# STM32L4S5 register map
File version: 2.2
CPU: CM4 r0p1, little endian, MPU, FPU, 4 interrupt priority bits
Registers are 32-bit, read-write, reset 0x0 unless marked. A register's access mark holds for its fields unless they carry their own. Offsets are from the block's base; [hi:lo] are bit positions.

## OCTOSPI1 — OctoSPI
Base 0xA0001000
Same registers: OCTOSPI2 0xA0001400
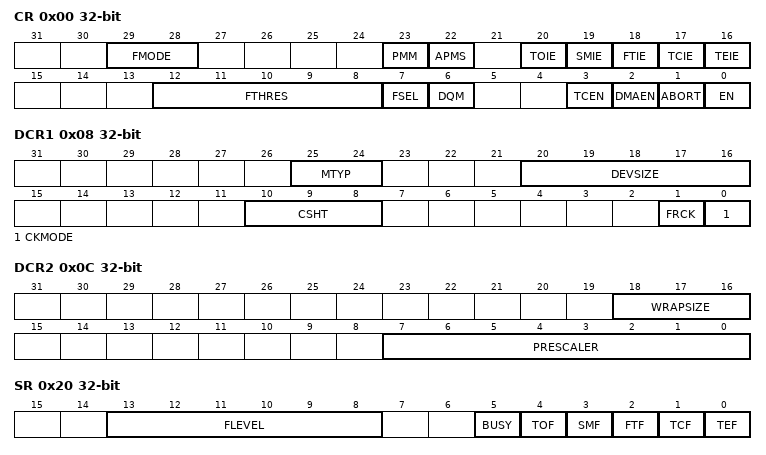
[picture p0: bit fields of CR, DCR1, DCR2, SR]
0x00 CR — control register
  [29:28] FMODE — Functional mode
  [23] PMM — Polling match mode
  [22] APMS — Automatic poll mode stop
  [20] TOIE — TimeOut interrupt enable
  [19] SMIE — Status match interrupt enable
  [18] FTIE — FIFO threshold interrupt enable
  [17] TCIE — Transfer complete interrupt enable
  [16] TEIE — Transfer error interrupt enable
  [12:8] FTHRES — IFO threshold level
  [7] FSEL — FLASH memory selection
  [6] DQM — Dual-quad mode
  [3] TCEN — Timeout counter enable
  [2] DMAEN — DMA enable
  [1] ABORT — Abort request
  [0] EN — Enable
0x08 DCR1 — device configuration register
  [25:24] MTYP — Memory type
  [20:16] DEVSIZE — Device size
  [10:8] CSHT — Chip-select high time
  [1] FRCK — Free running clock
  [0] CKMODE — Mode 0 / mode 3
0x0C DCR2 — device configuration register 2
  [18:16] WRAPSIZE
  [7:0] PRESCALER — Clock prescaler
0x10 DCR3 — device configuration register 3
  [20:16] CSBOUND — CS boundary
0x20 SR — status register
  [13:8] FLEVEL — FIFO level
  [5] BUSY
  [4] TOF — Timeout flag
  [3] SMF — Status match flag
  [2] FTF — FIFO threshold flag
  [1] TCF — Transfer complete flag
  [0] TEF — Transfer error flag
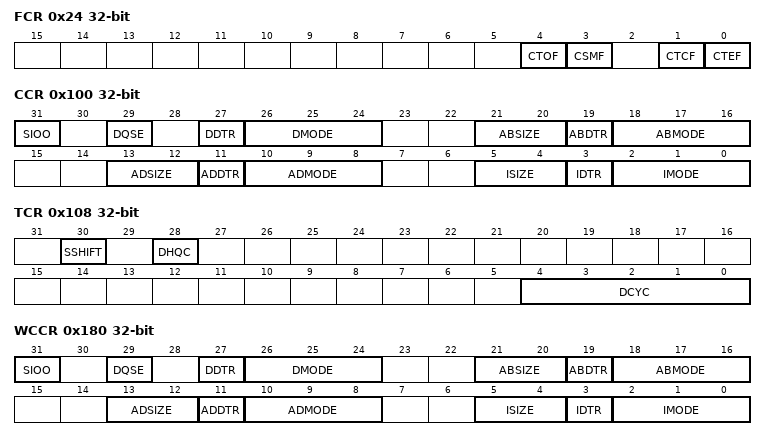
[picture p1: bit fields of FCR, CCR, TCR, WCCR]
0x24 FCR wo — flag clear register
  [4] CTOF — Clear timeout flag
  [3] CSMF — Clear status match flag
  [1] CTCF — Clear transfer complete flag
  [0] CTEF — Clear transfer error flag
0x40 DLR — data length register
  [31:0] DL — Data length
0x48 AR — address register
  [31:0] ADDRESS
0x50 DR — data register
  [31:0] DATA
0x80 PSMKR — polling status mask register
  [31:0] MASK — Status mask
0x88 PSMAR — polling status match register
  [31:0] MATCH — Status match
0x90 PIR — polling interval register
  [15:0] INTERVAL — Polling interval
0x100 CCR — communication configuration register
  [31] SIOO — Send instruction only once mode
  [29] DQSE — DQS enable
  [27] DDTR — Alternate bytes double transfer rate
  [26:24] DMODE — Data mode
  [21:20] ABSIZE — Alternate bytes size
  [19] ABDTR — Alternate bytes double transfer rate
  [18:16] ABMODE — Alternate byte mode
  [13:12] ADSIZE — Address size
  [11] ADDTR — Address double transfer rate
  [10:8] ADMODE — Address mode
  [5:4] ISIZE — Instruction size
  [3] IDTR — Instruction double transfer rate
  [2:0] IMODE — Instruction mode
0x108 TCR — timing configuration register
  [30] SSHIFT — Sample shift
  [28] DHQC — Delay hold quarter cycle
  [4:0] DCYC — Number of dummy cycles
0x110 IR — instruction register
  [31:0] INSTRUCTION
0x120 ABR — alternate bytes register
  [31:0] ALTERNATE — Alternate bytes
0x130 LPTR — low-power timeout register
  [15:0] TIMEOUT — Timeout period
0x180 WCCR — write communication configuration register
  [31] SIOO — Send instruction only once mode
  [29] DQSE — DQS enable
  [27] DDTR — alternate bytes double transfer rate
  [26:24] DMODE — Data mode
  [21:20] ABSIZE — Alternate bytes size
  [19] ABDTR — Alternate bytes double transfer rate
  [18:16] ABMODE — Alternate byte mode
  [13:12] ADSIZE — Address size
  [11] ADDTR — Address double transfer rate
  [10:8] ADMODE — Address mode
  [5:4] ISIZE — Instruction size
  [3] IDTR — Instruction double transfer rate
  [2:0] IMODE — Instruction mode
0x188 WTCR — write timing configuration register
  [4:0] DCYC — Number of dummy cycles
0x190 WIR — write instruction register
  [31:0] INSTRUCTION
0x1A0 WABR — write alternate bytes register
  [31:0] ALTERNATE — Alternate bytes
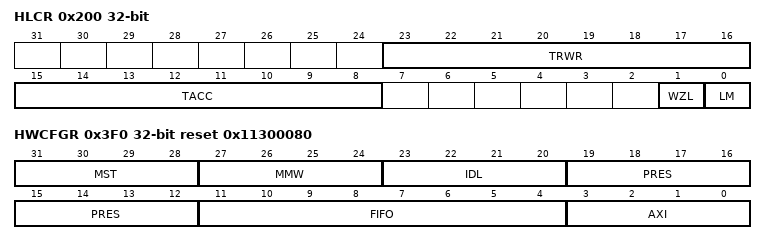
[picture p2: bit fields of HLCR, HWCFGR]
0x200 HLCR — HyperBusTM latency configuration register
  [23:16] TRWR — Read write recovery time
  [15:8] TACC — Access time
  [1] WZL — Write zero latency
  [0] LM — Latency mode
0x3F0 HWCFGR ro reset 0x11300080 — HW configuration register
  [31:28] MST — Master
  [27:24] MMW — Memory map write
  [23:20] IDL — ID Length
  [19:12] PRES — Prescaler
  [11:4] FIFO — FIFO depth
  [3:0] AXI — AXI interface
0x3F4 VER ro reset 0x10 — version register
  [7:0] VER — Version
0x3F8 ID ro reset 0x140041 — identification
  [31:0] ID — Identification
0x3FC MID ro reset 0xA3C5DD01 — magic ID
  [31:0] MID — Magic ID

## Notices in the file
Copyright (c) 2025 STMicroelectronics.
SPDX-License-Identifier: Apache-2.0
Licensed under the Apache License, Version 2.0 (the "License");
you may not use this file except in compliance with the License.
You may obtain a copy of the License at
http://www.apache.org/licenses/LICENSE-2.0
Unless required by applicable law or agreed to in writing, software
distributed under the License is distributed on an "AS IS" BASIS,
WITHOUT WARRANTIES OR CONDITIONS OF ANY KIND, either express or implied.
See the License for the specific language governing permissions and
limitations under the License.
